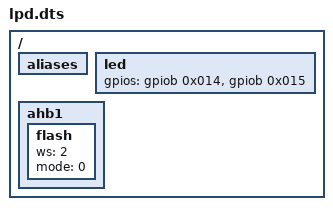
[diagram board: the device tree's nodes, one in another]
/dts-v1/;
/include/ "stm32f429.dtsi"

/ {
	aliases
	{
	};

	led
	{
		gpios = <&gpiob 0x014 2>,  // cs, PB0, output 0
				<&gpiob 0x015 2>;  // reset, PA1, output 0
	};

	ahb1
	{
		flash: flash
		{
			ws = <2>;
			mode = <0>;
		};
	};

};
